# ET6801 register map
Vendor: ETMCU Inc.; File version: v0.0.1
CPU: CM7 r2p1, little endian, MPU, FPU, I-cache, D-cache, ITCM, DTCM, 4 interrupt priority bits
Registers are 32-bit, read-write, reset 0x0 unless marked. A register's access mark holds for its fields unless they carry their own. Offsets are from the block's base; [hi:lo] are bit positions; {n}, {i} and the like mark numbered series.

## IOMUX — Provide an overview of the purpose and functionality of the peripheral: ioc
Base 0x4040F000
0x00 HID reset 0x89942292
  [31:0] ID — ID number, can be mofified by software
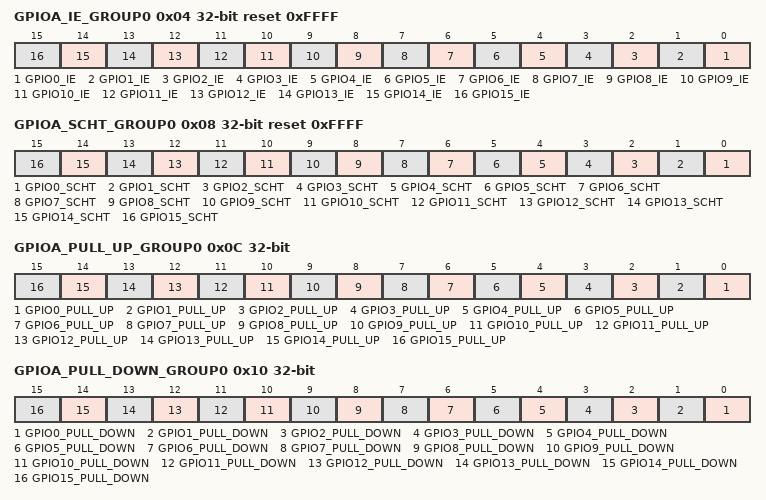
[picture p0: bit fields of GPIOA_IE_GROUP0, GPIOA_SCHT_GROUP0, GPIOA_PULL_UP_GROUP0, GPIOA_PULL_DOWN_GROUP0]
0x04 GPIOA_IE_GROUP0 reset 0xFFFF
  [n] GPIO{n}_IE (n=0..15) — GPIO{n} input enable
0x08 GPIOA_SCHT_GROUP0 reset 0xFFFF
  [n] GPIO{n}_SCHT (n=0..15) — GPIO{n} schmmitt ctrl
0x0C GPIOA_PULL_UP_GROUP0
  [n] GPIO{n}_PULL_UP (n=0..15) — GPIO{n} pull up control. 0:Null 1:pull up
0x10 GPIOA_PULL_DOWN_GROUP0
  [n] GPIO{n}_PULL_DOWN (n=0..15) — GPIO{n} pull down control. 0:Null 1:pull down
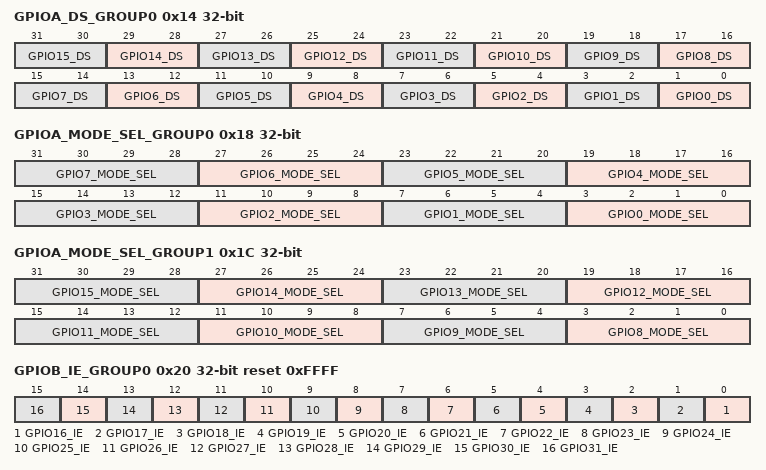
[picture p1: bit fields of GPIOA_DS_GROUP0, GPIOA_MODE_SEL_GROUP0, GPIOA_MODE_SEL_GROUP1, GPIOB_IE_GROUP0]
0x14 GPIOA_DS_GROUP0
  [2n+1:2n] GPIO{n}_DS (n=0..15) — GPIO{n} drive strength
0x18 GPIOA_MODE_SEL_GROUP0
  [4n+3:4n] GPIO{n}_MODE_SEL (n=0..7) — GPIO{n} emergency stop en ctrl by smc
0x1C GPIOA_MODE_SEL_GROUP1
  [4n-29:4n-32] GPIO{n}_MODE_SEL (n=8..15) — GPIO{n} emergency stop en ctrl by smc
0x20 GPIOB_IE_GROUP0 reset 0xFFFF
  [n-16] GPIO{n}_IE (n=16..31) — GPIO{n} input enable
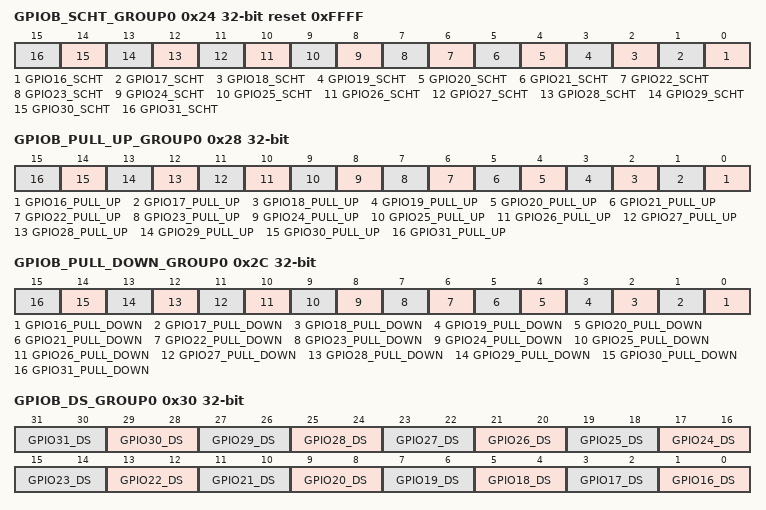
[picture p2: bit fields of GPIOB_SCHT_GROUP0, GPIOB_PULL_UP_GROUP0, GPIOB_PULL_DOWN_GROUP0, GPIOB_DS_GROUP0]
0x24 GPIOB_SCHT_GROUP0 reset 0xFFFF
  [n-16] GPIO{n}_SCHT (n=16..31) — GPIO{n} schmmitt ctrl
0x28 GPIOB_PULL_UP_GROUP0
  [n-16] GPIO{n}_PULL_UP (n=16..31) — GPIO{n} pull up control. 0:Null 1:pull up
0x2C GPIOB_PULL_DOWN_GROUP0
  [n-16] GPIO{n}_PULL_DOWN (n=16..31) — GPIO{n} pull down control. 0:Null 1:pull down
0x30 GPIOB_DS_GROUP0
  [2n-31:2n-32] GPIO{n}_DS (n=16..31) — GPIO{n} drive strength
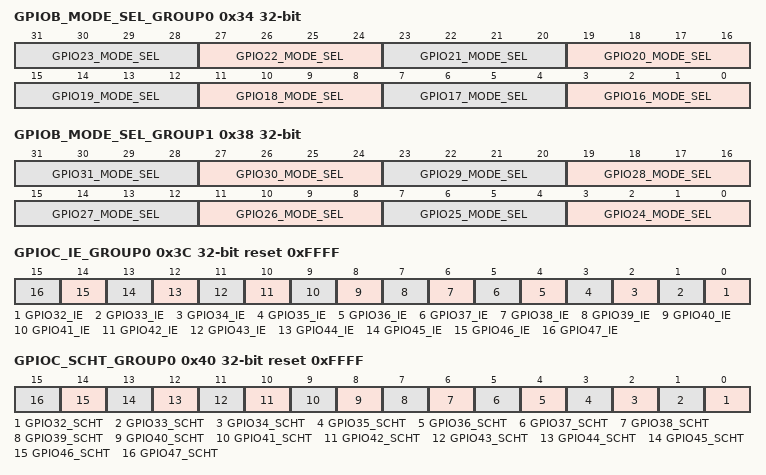
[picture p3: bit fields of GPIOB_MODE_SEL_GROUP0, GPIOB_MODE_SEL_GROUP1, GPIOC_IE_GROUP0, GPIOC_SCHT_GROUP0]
0x34 GPIOB_MODE_SEL_GROUP0
  [4n-61:4n-64] GPIO{n}_MODE_SEL (n=16..23) — GPIO{n} emergency stop en ctrl by smc
0x38 GPIOB_MODE_SEL_GROUP1
  [4n-93:4n-96] GPIO{n}_MODE_SEL (n=24..31) — GPIO{n} emergency stop en ctrl by smc
0x3C GPIOC_IE_GROUP0 reset 0xFFFF
  [n-32] GPIO{n}_IE (n=32..47) — GPIO{n} input enable
0x40 GPIOC_SCHT_GROUP0 reset 0xFFFF
  [n-32] GPIO{n}_SCHT (n=32..47) — GPIO{n} schmmitt ctrl
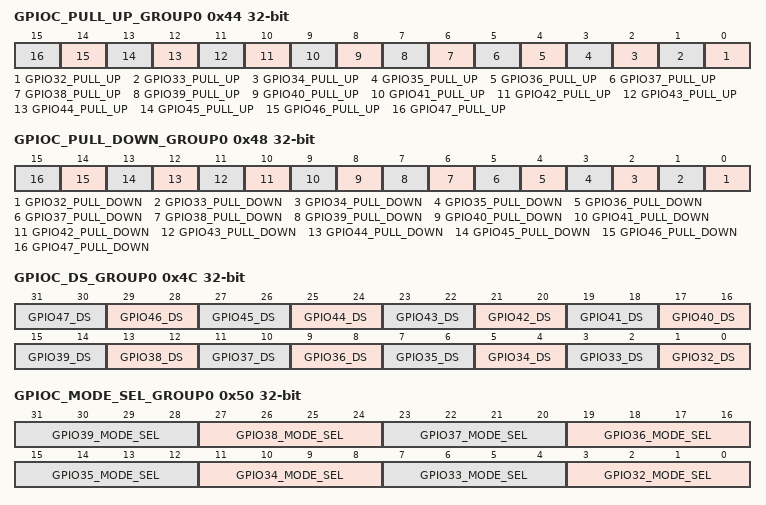
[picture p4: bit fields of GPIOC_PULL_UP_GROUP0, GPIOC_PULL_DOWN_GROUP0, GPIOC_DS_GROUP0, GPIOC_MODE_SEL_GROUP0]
0x44 GPIOC_PULL_UP_GROUP0
  [n-32] GPIO{n}_PULL_UP (n=32..47) — GPIO{n} pull up control. 0:Null 1:pull up
0x48 GPIOC_PULL_DOWN_GROUP0
  [n-32] GPIO{n}_PULL_DOWN (n=32..47) — GPIO{n} pull down control. 0:Null 1:pull down
0x4C GPIOC_DS_GROUP0
  [2n-63:2n-64] GPIO{n}_DS (n=32..47) — GPIO{n} drive strength
0x50 GPIOC_MODE_SEL_GROUP0
  [4n-125:4n-128] GPIO{n}_MODE_SEL (n=32..39) — GPIO{n} emergency stop en ctrl by smc
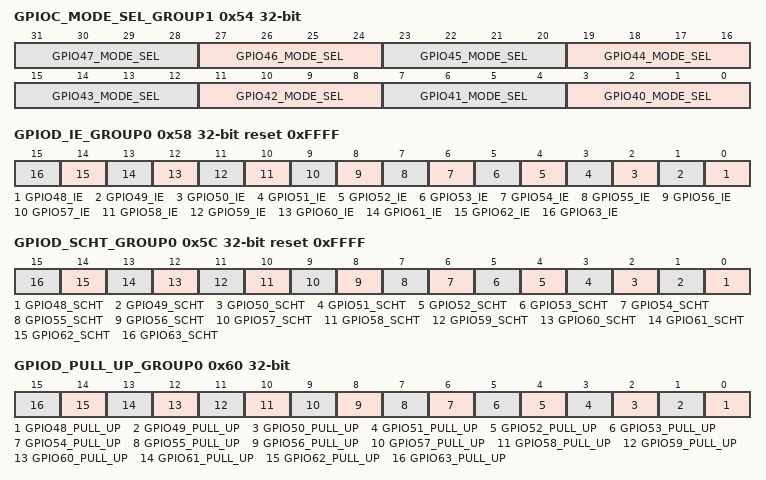
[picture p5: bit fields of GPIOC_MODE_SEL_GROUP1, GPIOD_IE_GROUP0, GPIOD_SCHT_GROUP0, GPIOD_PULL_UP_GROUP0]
0x54 GPIOC_MODE_SEL_GROUP1
  [4n-157:4n-160] GPIO{n}_MODE_SEL (n=40..47) — GPIO{n} emergency stop en ctrl by smc
0x58 GPIOD_IE_GROUP0 reset 0xFFFF
  [n-48] GPIO{n}_IE (n=48..63) — GPIO{n} input enable
0x5C GPIOD_SCHT_GROUP0 reset 0xFFFF
  [n-48] GPIO{n}_SCHT (n=48..63) — GPIO{n} schmmitt ctrl
0x60 GPIOD_PULL_UP_GROUP0
  [n-48] GPIO{n}_PULL_UP (n=48..63) — GPIO{n} pull up control. 0:Null 1:pull up
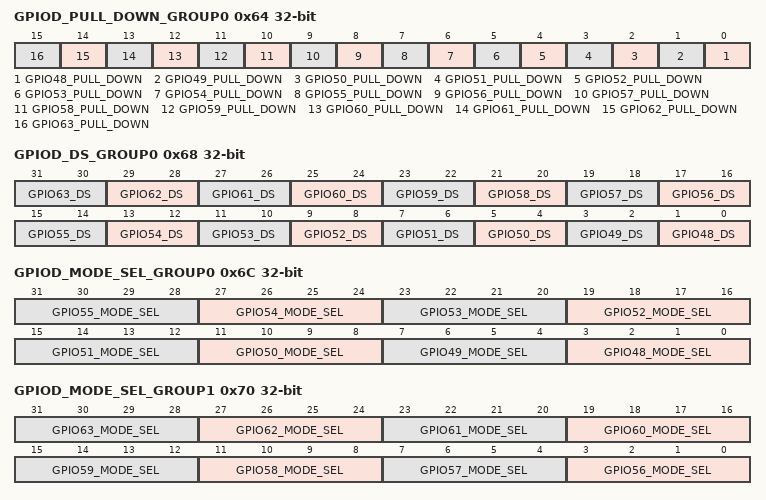
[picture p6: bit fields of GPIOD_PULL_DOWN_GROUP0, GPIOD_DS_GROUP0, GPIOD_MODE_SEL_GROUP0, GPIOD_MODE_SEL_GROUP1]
0x64 GPIOD_PULL_DOWN_GROUP0
  [n-48] GPIO{n}_PULL_DOWN (n=48..63) — GPIO{n} pull down control. 0:Null 1:pull down
0x68 GPIOD_DS_GROUP0
  [2n-95:2n-96] GPIO{n}_DS (n=48..63) — GPIO{n} drive strength
0x6C GPIOD_MODE_SEL_GROUP0
  [4n-189:4n-192] GPIO{n}_MODE_SEL (n=48..55) — GPIO{n} emergency stop en ctrl by smc
0x70 GPIOD_MODE_SEL_GROUP1
  [4n-221:4n-224] GPIO{n}_MODE_SEL (n=56..63) — GPIO{n} emergency stop en ctrl by smc
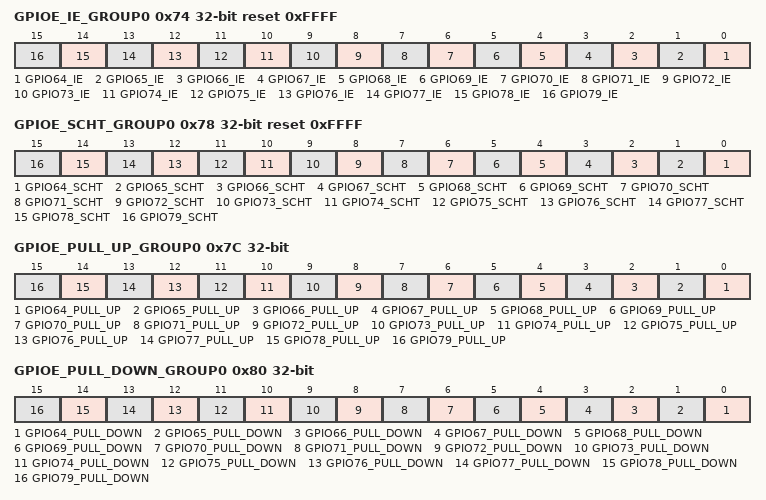
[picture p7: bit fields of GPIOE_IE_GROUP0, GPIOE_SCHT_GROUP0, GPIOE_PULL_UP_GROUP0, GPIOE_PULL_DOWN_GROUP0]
0x74 GPIOE_IE_GROUP0 reset 0xFFFF
  [n-64] GPIO{n}_IE (n=64..79) — GPIO{n} input enable
0x78 GPIOE_SCHT_GROUP0 reset 0xFFFF
  [n-64] GPIO{n}_SCHT (n=64..79) — GPIO{n} schmmitt ctrl
0x7C GPIOE_PULL_UP_GROUP0
  [n-64] GPIO{n}_PULL_UP (n=64..79) — GPIO{n} pull up control. 0:Null 1:pull up
0x80 GPIOE_PULL_DOWN_GROUP0
  [n-64] GPIO{n}_PULL_DOWN (n=64..79) — GPIO{n} pull down control. 0:Null 1:pull down
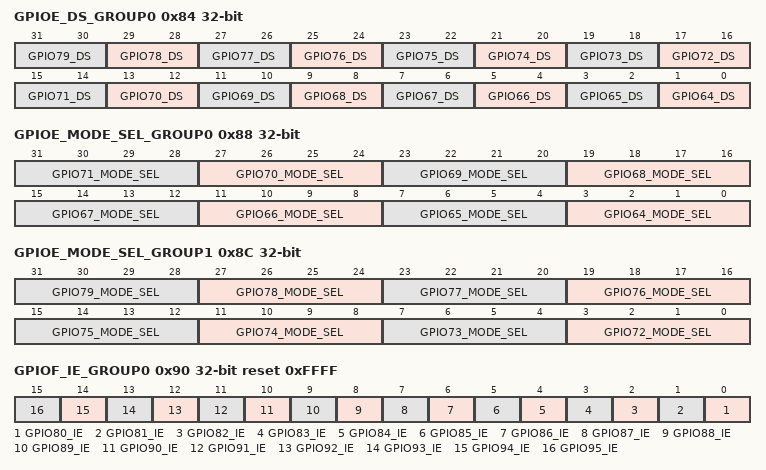
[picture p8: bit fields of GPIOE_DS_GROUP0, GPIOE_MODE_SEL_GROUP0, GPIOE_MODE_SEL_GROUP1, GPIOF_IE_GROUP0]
0x84 GPIOE_DS_GROUP0
  [2n-127:2n-128] GPIO{n}_DS (n=64..79) — GPIO{n} drive strength
0x88 GPIOE_MODE_SEL_GROUP0
  [4n-253:4n-256] GPIO{n}_MODE_SEL (n=64..71) — GPIO{n} emergency stop en ctrl by smc
0x8C GPIOE_MODE_SEL_GROUP1
  [4n-285:4n-288] GPIO{n}_MODE_SEL (n=72..79) — GPIO{n} emergency stop en ctrl by smc
0x90 GPIOF_IE_GROUP0 reset 0xFFFF
  [n-80] GPIO{n}_IE (n=80..95) — GPIO{n} input enable
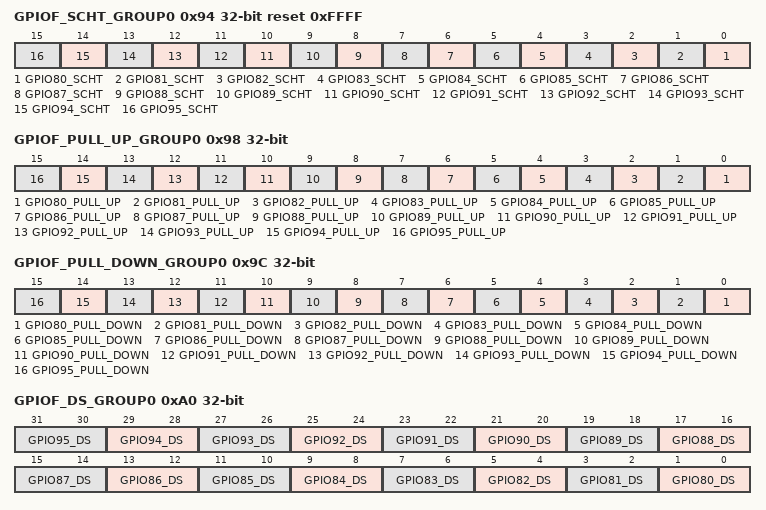
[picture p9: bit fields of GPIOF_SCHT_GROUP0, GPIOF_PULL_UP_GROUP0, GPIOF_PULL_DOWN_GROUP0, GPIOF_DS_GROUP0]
0x94 GPIOF_SCHT_GROUP0 reset 0xFFFF
  [n-80] GPIO{n}_SCHT (n=80..95) — GPIO{n} schmmitt ctrl
0x98 GPIOF_PULL_UP_GROUP0
  [n-80] GPIO{n}_PULL_UP (n=80..95) — GPIO{n} pull up control. 0:Null 1:pull up
0x9C GPIOF_PULL_DOWN_GROUP0
  [n-80] GPIO{n}_PULL_DOWN (n=80..95) — GPIO{n} pull down control. 0:Null 1:pull down
0xA0 GPIOF_DS_GROUP0
  [2n-159:2n-160] GPIO{n}_DS (n=80..95) — GPIO{n} drive strength
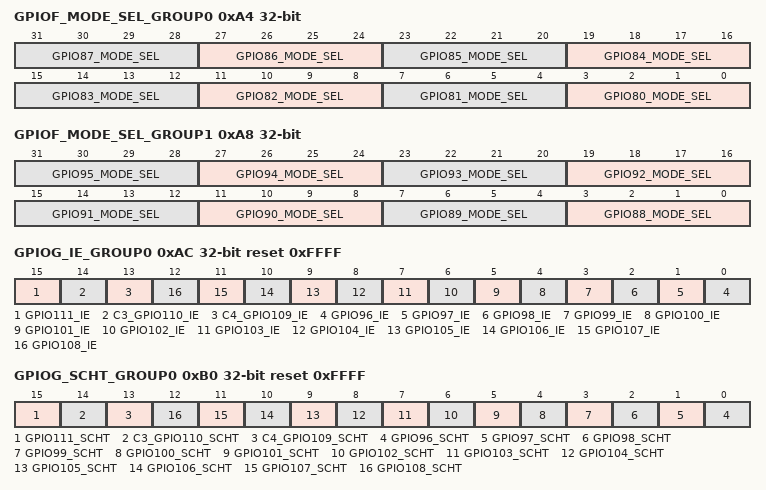
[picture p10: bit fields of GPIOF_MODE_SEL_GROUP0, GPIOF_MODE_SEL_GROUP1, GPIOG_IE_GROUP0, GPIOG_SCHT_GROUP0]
0xA4 GPIOF_MODE_SEL_GROUP0
  [4n-317:4n-320] GPIO{n}_MODE_SEL (n=80..87) — GPIO{n} emergency stop en ctrl by smc
0xA8 GPIOF_MODE_SEL_GROUP1
  [4n-349:4n-352] GPIO{n}_MODE_SEL (n=88..95) — GPIO{n} emergency stop en ctrl by smc
0xAC GPIOG_IE_GROUP0 reset 0xFFFF
  [15] GPIO111_IE — GPIO111 input enable
  [14] C3_GPIO110_IE — C3_GPIO110 input enable
  [13] C4_GPIO109_IE — C4_GPIO109 input enable
  [n-96] GPIO{n}_IE (n=96..108) — GPIO{n} input enable
0xB0 GPIOG_SCHT_GROUP0 reset 0xFFFF
  [15] GPIO111_SCHT — GPIO111 schmmitt ctrl
  [14] C3_GPIO110_SCHT — C3_GPIO110 schmmitt ctrl
  [13] C4_GPIO109_SCHT — C4_GPIO109 schmmitt ctrl
  [n-96] GPIO{n}_SCHT (n=96..108) — GPIO{n} schmmitt ctrl
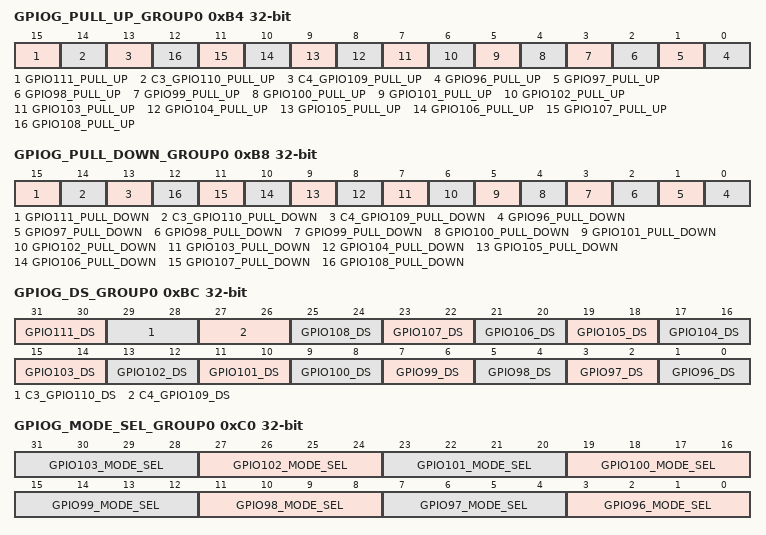
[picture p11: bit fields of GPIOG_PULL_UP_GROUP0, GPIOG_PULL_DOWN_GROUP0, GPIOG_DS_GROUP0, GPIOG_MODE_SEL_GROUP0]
0xB4 GPIOG_PULL_UP_GROUP0
  [15] GPIO111_PULL_UP — GPIO111 pull up control. 0:Null 1:pull up
  [14] C3_GPIO110_PULL_UP — C3_GPIO110 pull up control. 0:Null 1:pull up
  [13] C4_GPIO109_PULL_UP — C4_GPIO109 pull up control. 0:Null 1:pull up
  [n-96] GPIO{n}_PULL_UP (n=96..108) — GPIO{n} pull up control. 0:Null 1:pull up
0xB8 GPIOG_PULL_DOWN_GROUP0
  [15] GPIO111_PULL_DOWN — GPIO111 pull down control. 0:Null 1:pull down
  [14] C3_GPIO110_PULL_DOWN — C3_GPIO110 pull down control. 0:Null 1:pull down
  [13] C4_GPIO109_PULL_DOWN — C4_GPIO109 pull down control. 0:Null 1:pull down
  [n-96] GPIO{n}_PULL_DOWN (n=96..108) — GPIO{n} pull down control. 0:Null 1:pull down
0xBC GPIOG_DS_GROUP0
  [31:30] GPIO111_DS — GPIO111 drive strength
  [29:28] C3_GPIO110_DS — C3_GPIO110 drive strength
  [27:26] C4_GPIO109_DS — C4_GPIO109 drive strength
  [2n-191:2n-192] GPIO{n}_DS (n=96..108) — GPIO{n} drive strength
0xC0 GPIOG_MODE_SEL_GROUP0
  [4n-381:4n-384] GPIO{n}_MODE_SEL (n=96..103) — GPIO{n} emergency stop en ctrl by smc
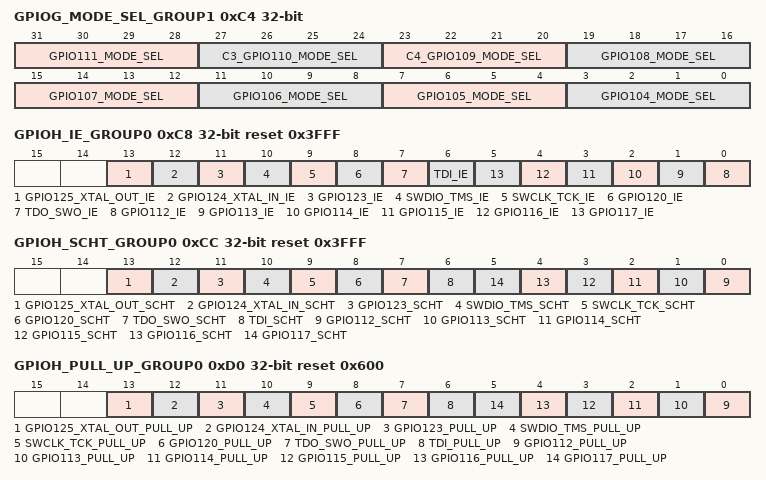
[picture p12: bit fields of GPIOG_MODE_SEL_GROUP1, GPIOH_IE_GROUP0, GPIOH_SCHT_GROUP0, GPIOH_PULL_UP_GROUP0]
0xC4 GPIOG_MODE_SEL_GROUP1
  [31:28] GPIO111_MODE_SEL — GPIO111 emergency stop en ctrl by smc
  [27:24] C3_GPIO110_MODE_SEL — C3_GPIO110 emergency stop en ctrl by smc
  [23:20] C4_GPIO109_MODE_SEL — C4_GPIO109 emergency stop en ctrl by smc
  [4n-413:4n-416] GPIO{n}_MODE_SEL (n=104..108) — GPIO{n} emergency stop en ctrl by smc
0xC8 GPIOH_IE_GROUP0 reset 0x3FFF
  [13] GPIO125_XTAL_OUT_IE — GPIO125_XTAL_OUT input enable
  [12] GPIO124_XTAL_IN_IE — GPIO124_XTAL_IN input enable
  [11] GPIO123_IE — GPIO123 input enable
  [10] SWDIO_TMS_IE — SWDIO_TMS input enable
  [9] SWCLK_TCK_IE — SWCLK_TCK input enable
  [8] GPIO120_IE — GPIO120 input enable
  [7] TDO_SWO_IE — TDO_SWO input enable
  [6] TDI_IE — TDI input enable
  [n-112] GPIO{n}_IE (n=112..117) — GPIO{n} input enable
0xCC GPIOH_SCHT_GROUP0 reset 0x3FFF
  [13] GPIO125_XTAL_OUT_SCHT — GPIO125_XTAL_OUT schmmitt ctrl
  [12] GPIO124_XTAL_IN_SCHT — GPIO124_XTAL_IN schmmitt ctrl
  [11] GPIO123_SCHT — GPIO123 schmmitt ctrl
  [10] SWDIO_TMS_SCHT — SWDIO_TMS schmmitt ctrl
  [9] SWCLK_TCK_SCHT — SWCLK_TCK schmmitt ctrl
  [8] GPIO120_SCHT — GPIO120 schmmitt ctrl
  [7] TDO_SWO_SCHT — TDO_SWO schmmitt ctrl
  [6] TDI_SCHT — TDI schmmitt ctrl
  [n-112] GPIO{n}_SCHT (n=112..117) — GPIO{n} schmmitt ctrl
0xD0 GPIOH_PULL_UP_GROUP0 reset 0x600
  [13] GPIO125_XTAL_OUT_PULL_UP — GPIO125_XTAL_OUT pull up control. 0:Null 1:pull up
  [12] GPIO124_XTAL_IN_PULL_UP — GPIO124_XTAL_IN pull up control. 0:Null 1:pull up
  [11] GPIO123_PULL_UP — GPIO123 pull up control. 0:Null 1:pull up
  [10] SWDIO_TMS_PULL_UP — SWDIO_TMS pull up control. 0:Null 1:pull up
  [9] SWCLK_TCK_PULL_UP — SWCLK_TCK pull up control. 0:Null 1:pull up
  [8] GPIO120_PULL_UP — GPIO120 pull up control. 0:Null 1:pull up
  [7] TDO_SWO_PULL_UP — TDO_SWO pull up control. 0:Null 1:pull up
  [6] TDI_PULL_UP — TDI pull up control. 0:Null 1:pull up
  [n-112] GPIO{n}_PULL_UP (n=112..117) — GPIO{n} pull up control. 0:Null 1:pull up
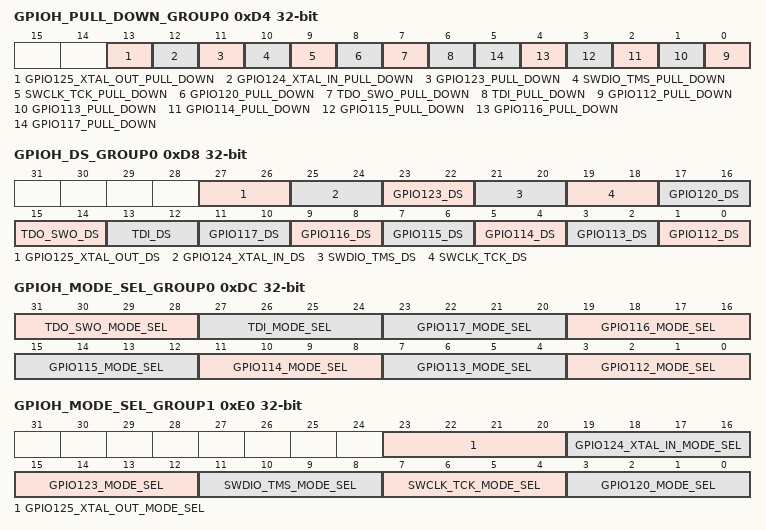
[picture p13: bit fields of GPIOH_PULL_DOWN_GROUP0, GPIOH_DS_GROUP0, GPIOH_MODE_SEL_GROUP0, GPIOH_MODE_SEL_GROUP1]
0xD4 GPIOH_PULL_DOWN_GROUP0
  [13] GPIO125_XTAL_OUT_PULL_DOWN — GPIO125_XTAL_OUT pull down control. 0:Null 1:pull down
  [12] GPIO124_XTAL_IN_PULL_DOWN — GPIO124_XTAL_IN pull down control. 0:Null 1:pull down
  [11] GPIO123_PULL_DOWN — GPIO123 pull down control. 0:Null 1:pull down
  [10] SWDIO_TMS_PULL_DOWN — SWDIO_TMS pull down control. 0:Null 1:pull down
  [9] SWCLK_TCK_PULL_DOWN — SWCLK_TCK pull down control. 0:Null 1:pull down
  [8] GPIO120_PULL_DOWN — GPIO120 pull down control. 0:Null 1:pull down
  [7] TDO_SWO_PULL_DOWN — TDO_SWO pull down control. 0:Null 1:pull down
  [6] TDI_PULL_DOWN — TDI pull down control. 0:Null 1:pull down
  [n-112] GPIO{n}_PULL_DOWN (n=112..117) — GPIO{n} pull down control. 0:Null 1:pull down
0xD8 GPIOH_DS_GROUP0
  [27:26] GPIO125_XTAL_OUT_DS — GPIO125_XTAL_OUT drive strength
  [25:24] GPIO124_XTAL_IN_DS — GPIO124_XTAL_IN drive strength
  [23:22] GPIO123_DS — GPIO123 drive strength
  [21:20] SWDIO_TMS_DS — SWDIO_TMS drive strength
  [19:18] SWCLK_TCK_DS — SWCLK_TCK drive strength
  [17:16] GPIO120_DS — GPIO120 drive strength
  [15:14] TDO_SWO_DS — TDO_SWO drive strength
  [13:12] TDI_DS — TDI drive strength
  [2n-223:2n-224] GPIO{n}_DS (n=112..117) — GPIO{n} drive strength
0xDC GPIOH_MODE_SEL_GROUP0
  [31:28] TDO_SWO_MODE_SEL — TDO_SWO emergency stop en ctrl by smc
  [27:24] TDI_MODE_SEL — TDI emergency stop en ctrl by smc
  [4n-445:4n-448] GPIO{n}_MODE_SEL (n=112..117) — GPIO{n} emergency stop en ctrl by smc
0xE0 GPIOH_MODE_SEL_GROUP1
  [23:20] GPIO125_XTAL_OUT_MODE_SEL — GPIO125_XTAL_OUT emergency stop en ctrl by smc
  [19:16] GPIO124_XTAL_IN_MODE_SEL — GPIO124_XTAL_IN emergency stop en ctrl by smc
  [15:12] GPIO123_MODE_SEL — GPIO123 emergency stop en ctrl by smc
  [11:8] SWDIO_TMS_MODE_SEL — SWDIO_TMS emergency stop en ctrl by smc
  [7:4] SWCLK_TCK_MODE_SEL — SWCLK_TCK emergency stop en ctrl by smc
  [3:0] GPIO120_MODE_SEL — GPIO120 emergency stop en ctrl by smc
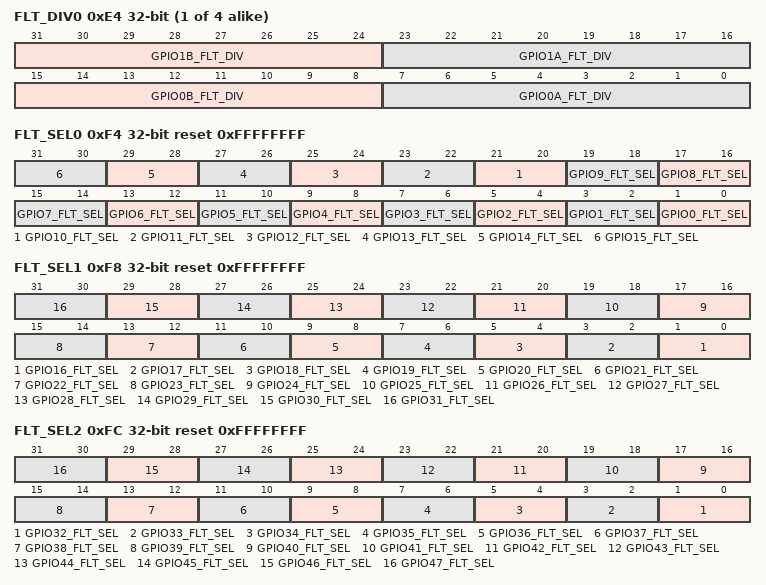
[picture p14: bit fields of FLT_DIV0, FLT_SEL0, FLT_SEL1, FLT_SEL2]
{0xE4+4i} FLT_DIV{i} (i=0..3)
  [31:24] GPIO{2i+1}B_FLT_DIV — samle div
  [23:16] GPIO{2i+1}A_FLT_DIV — samle div
  [15:8] GPIO{2i}B_FLT_DIV — samle div
  [7:0] GPIO{2i}A_FLT_DIV — samle div
0xF4 FLT_SEL0 reset 0xFFFFFFFF
  [2n+1:2n] GPIO{n}_FLT_SEL (n=0..15) — flt path select:
0xF8 FLT_SEL1 reset 0xFFFFFFFF
  [2n-31:2n-32] GPIO{n}_FLT_SEL (n=16..31) — flt path select:
0xFC FLT_SEL2 reset 0xFFFFFFFF
  [2n-63:2n-64] GPIO{n}_FLT_SEL (n=32..47) — flt path select:
0x100 FLT_SEL3 reset 0xFFFFFFFF
  [2n-95:2n-96] GPIO{n}_FLT_SEL (n=48..63) — flt path select:
0x104 FLT_SEL4 reset 0xFFFFFFFF
  [2n-127:2n-128] GPIO{n}_FLT_SEL (n=64..79) — flt path select:
0x108 FLT_SEL5 reset 0xFFFFFFFF
  [2n-159:2n-160] GPIO{n}_FLT_SEL (n=80..95) — flt path select:
0x10C FLT_SEL6 reset 0xFFFFFFFF
  [31:30] GPIO111_FLT_SEL — flt path select:
  [29:28] C3_GPIO110_FLT_SEL — flt path select:
  [27:26] C4_GPIO109_FLT_SEL — flt path select:
  [2n-191:2n-192] GPIO{n}_FLT_SEL (n=96..108) — flt path select:
0x110 FLT_SEL7 reset 0xFFFFFFF
  [27:26] GPIO125_XTAL_OUT_FLT_SEL — flt path select:
  [25:24] GPIO124_XTAL_IN_FLT_SEL — flt path select:
  [23:22] GPIO123_FLT_SEL — flt path select:
  [21:20] SWDIO_TMS_FLT_SEL — flt path select:
  [19:18] SWCLK_TCK_FLT_SEL — flt path select:
  [17:16] GPIO120_FLT_SEL — flt path select:
  [15:14] TDO_SWO_FLT_SEL — flt path select:
  [13:12] TDI_FLT_SEL — flt path select:
  [2n-223:2n-224] GPIO{n}_FLT_SEL (n=112..117) — flt path select:
0x114 TID reset 0x5EDDD014
  [31:0] ID — ID number, can be mofified by software
